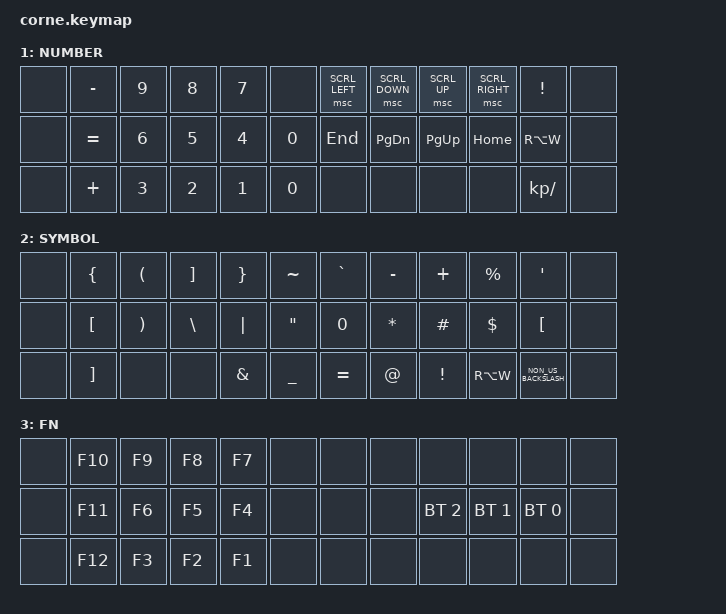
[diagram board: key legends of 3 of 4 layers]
/*
 * Copyright (c) 2020 The ZMK Contributors
 *
 * SPDX-License-Identifier: MIT
 */

#define ZMK_POINTING_DEFAULT_MOVE_VAL 1200  // 600
#define ZMK_POINTING_DEFAULT_SCRL_VAL 25   // 10

#include <input/processors.dtsi>
#include <zephyr/dt-bindings/input/input-event-codes.h>
#include <behaviors.dtsi>
#include <dt-bindings/zmk/bt.h>
#include <dt-bindings/zmk/keys.h>
#include <dt-bindings/zmk/outputs.h>
#include <dt-bindings/zmk/pointing.h>
#include <dt-bindings/zmk/rgb.h>

&mmv_input_listener { input-processors = <&zip_xy_scaler 2 1>; };

&msc_input_listener { input-processors = <&zip_scroll_scaler 2 1>; };

&msc {
    acceleration-exponent = <1>;      // 0
    time-to-max-speed-ms = <500>;       // 300
    delay-ms = <0>;                   // 0
};

&mmv {
    time-to-max-speed-ms = <500>;
    acceleration-exponent = <1>;
    trigger-period-ms = <16>;
};

/ {

    keymap {
      compatible = "zmk,keymap";
      locale = "br-abnt2";

      default_layer {
        display-name = "QWERTY";
        bindings = <
&none  &kp Q  &kp W  &kp E      &kp R     &kp T           &kp Y     &kp U  &kp I      &kp O      &kp P     &none
&none  &kp A  &kp S  &kp D      &kp F     &kp G           &kp H     &kp J  &kp K      &kp L      &kp SEMI  &none
&none  &kp Z  &kp X  &kp C      &kp V     &kp B           &kp N     &kp M  &kp COMMA  &kp DOT    &kp FSLH  &none
&mo 1  &mo 2  &mo 3 &kp ENTER  &kp SPACE  &kp DELETE &kp TAB  &kp KP_DIVIDE  &kp BSPC  &kp TAB   &kp MINUS  &kp LS(FSLH)
&kp ESC  &kp LSHFT  &kp LCTRL  &kp LALT &kp LEFT_ARROW  &kp DOWN  &kp UP  &kp RIGHT  &mkp LCLK  &mkp RCLK  &mkp MCLK   &kp GRAVE
        >;
      };

      lower_layer {
        display-name = "NUMBER";
        bindings = <
&none  &kp MINUS  &kp N9     &kp N8     &kp N7    &none             &msc SCRL_LEFT  &msc SCRL_DOWN  &msc SCRL_UP  &msc SCRL_RIGHT  &kp EXCL       &none
&none  &kp EQUAL  &kp N6     &kp N5     &kp N4    &kp N0            &kp END         &kp PG_DN       &kp PG_UP     &kp  HOME        &kp RA(W)      &none
&none  &kp PLUS   &kp N3     &kp N2     &kp N1    &kp N0            &none           &none           &none         &none            &kp KP_DIVIDE  &none
        >;
      };

      raise_layer {
        display-name = "SYMBOL";
        bindings = <
&none  &kp LEFT_BRACE  &kp LEFT_PARENTHESIS   &kp RIGHT_BRACKET      &kp RIGHT_BRACE  &kp TILDE               &kp GRAVE  &kp MINUS   &kp PLUS   &kp PRCNT  &kp SQT               &none
&none  &kp LBKT        &kp RIGHT_PARENTHESIS  &kp BSLH               &kp PIPE         &kp DOUBLE_QUOTES       &kp N0     &kp STAR    &kp HASH   &kp DLLR   &kp LEFT_BRACKET      &none
&none  &kp RBKT        &none                  &none                  &kp AMPS         &kp UNDERSCORE          &kp EQUAL  &kp AT      &kp EXCL   &kp RA(W)  &kp NON_US_BACKSLASH  &none
        >;
      };

      fn_layer {
        display-name = "FN";
        bindings = <
&none  &kp F10  &kp F9  &kp F8  &kp F7  &none         &none  &none  &none         &none         &none         &none
&none  &kp F11  &kp F6  &kp F5  &kp F4  &none         &none  &none  &bt BT_SEL 2  &bt BT_SEL 1  &bt BT_SEL 0  &none
&none  &kp F12  &kp F3  &kp F2  &kp F1  &none         &none  &none  &none         &none         &none         &none
        >;
      };

    };
};
